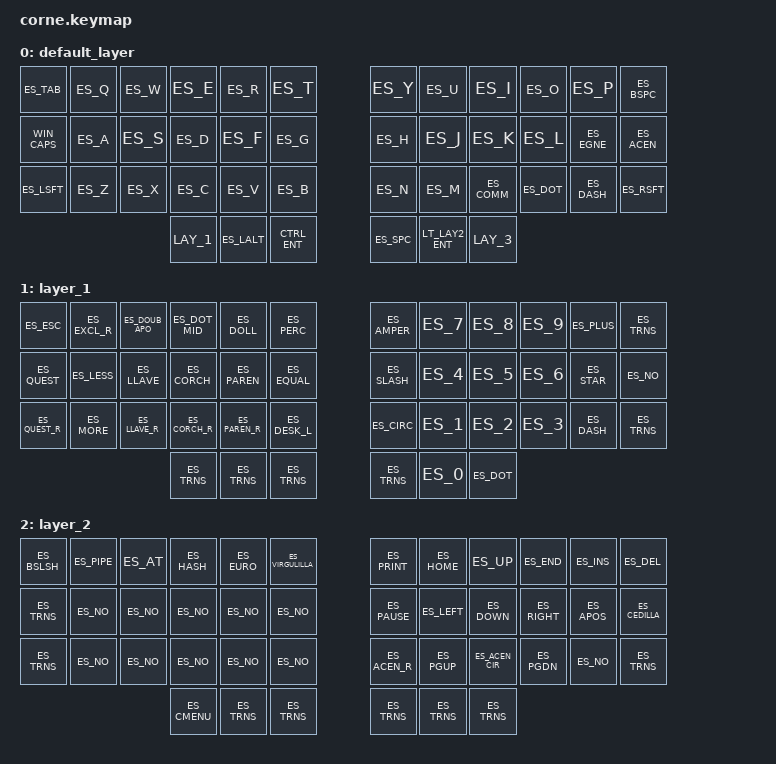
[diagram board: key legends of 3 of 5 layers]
#include <behaviors.dtsi>
#include <dt-bindings/zmk/keys.h>
#include <dt-bindings/zmk/bt.h>
#include <dt-bindings/zmk/rgb.h>
#include "via_spanish.h"

/ {
    keymap {
        compatible = "zmk,keymap";

        default_layer {
            bindings = <
ES_TAB ES_Q ES_W ES_E ES_R ES_T         ES_Y  ES_U ES_I ES_O ES_P ES_BSPC
WIN_CAPS ES_A ES_S ES_D ES_F ES_G       ES_H ES_J ES_K ES_L ES_EGNE ES_ACEN
ES_LSFT ES_Z ES_X ES_C ES_V ES_B        ES_N ES_M ES_COMM ES_DOT ES_DASH ES_RSFT
LAY_1 ES_LALT CTRL_ENT                  ES_SPC LT_LAY2_ENT  LAY_3
            >; 
        };

        layer_1 {
            bindings = <
//esc !"·$%                                                         & 789+ trns
ES_ESC ES_EXCL_R ES_DOUB_APO ES_DOT_MID ES_DOLL ES_PERC             ES_AMPER ES_7  ES_8   ES_9 ES_PLUS    ES_TRNS 
//¿<{[(=                                                            /456* NO
ES_QUEST ES_LESS ES_LLAVE ES_CORCH ES_PAREN ES_EQUAL                ES_SLASH ES_4 ES_5 ES_6 ES_STAR ES_NO
// ?>}]) SYS_RESET                                                  º123- TRNS 
ES_QUEST_R ES_MORE ES_LLAVE_R ES_CORCH_R ES_PAREN_R ES_DESK_L    ES_CIRC ES_1 ES_2 ES_3 ES_DASH ES_TRNS
ES_TRNS ES_TRNS ES_TRNS                                             ES_TRNS ES_0 ES_DOT
            >;
        };

        layer_2 {
            bindings = <
// \|@# €~                                                            PRINT HOME UP END INS DEL
ES_BSLSH ES_PIPE ES_AT ES_HASH ES_EURO ES_VIRGULILLA                ES_PRINT ES_HOME ES_UP ES_END ES_INS ES_DEL
// TRNS NO NO  NO NO NO                                      PAUSE  LEFT DOWN RIGHT  '  ç
ES_TRNS ES_NO ES_NO ES_NO ES_NO ES_NO                       ES_PAUSE ES_LEFT ES_DOWN ES_RIGHT ES_APOS ES_CEDILLA
//                                                          ` PGUP ^ PGDN NO TRNS
ES_TRNS ES_NO ES_NO ES_NO ES_NO ES_NO                       ES_ACEN_R ES_PGUP ES_ACEN_CIR ES_PGDN ES_NO ES_TRNS
// menu
ES_CMENU ES_TRNS ES_TRNS                                    ES_TRNS ES_TRNS ES_TRNS
            >;
        };

        layer_3 {
            bindings = <
ES_NO ES_F1 ES_F2 ES_F3 ES_F4 ES_F5                                 ES_F6 ES_F7 ES_F8 ES_F9 ES_F10 ES_F11
RGB_TOGG RGB_EFFO RGB_EFRE ES_NO &fixme_natural_macro BT_CLEAR      ES_NO BT_0 BT_1 BT_2 BT_3 ES_F12
ES_NO ES_NO ES_NO ES_NO ES_NO ES_NO                                 ES_NO ES_DESK_L ES_DESK_R ES_NO ES_NO ES_TRNS
ES_TRNS ES_TRNS ES_TRNS                                             ES_TRNS ES_TRNS ES_TRNS
            >;
        };

        layer_4 {
            bindings = <
ES_NO ES_NO ES_NO ES_NO ES_NO   ES_NO ES_NO ES_NO ES_NO ES_NO 
ES_NO ES_NO ES_NO ES_NO ES_NO   ES_NO ES_NO ES_NO ES_NO ES_NO 
ES_NO ES_NO ES_NO ES_NO ES_NO   ES_NO ES_NO ES_NO ES_NO ES_NO 
ES_TRNS ES_TRNS ES_TRNS         ES_TRNS  ES_TRNS
            >;
        };
    };
};
// 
